# STM32F777 register map
File version: 1.6
CPU: CM7 r0p1, little endian, MPU, FPU, 4 interrupt priority bits
Registers are 32-bit, read-write, reset 0x0 unless marked. A register's access mark holds for its fields unless they carry their own. Offsets are from the block's base; [hi:lo] are bit positions; {n}, {i} and the like mark numbered series.

## TIM6 — Basic timers
Base 0x40001000
Same registers: TIM7 0x40001400
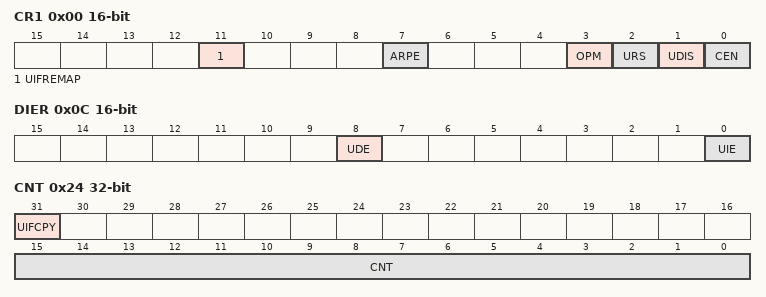
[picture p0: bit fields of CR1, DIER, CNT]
0x00 CR1 16-bit — control register 1
  [11] UIFREMAP — UIF status bit remapping
  [7] ARPE — Auto-reload preload enable
    0=Disabled (TIMx_APRR register is not buffered); 1=Enabled (TIMx_APRR register is buffered)
  [3] OPM — One-pulse mode
    0=Disabled (Counter is not stopped at update event); 1=Enabled (Counter stops counting at the next update event (clearing the CEN bit))
  [2] URS — Update request source
    0=AnyEvent (Any of counter overflow/underflow, setting UG, or update through slave mode, generates an update interrupt or DMA request); 1=CounterOnly (Only counter overflow/underflow generates an update interrupt or DMA request)
  [1] UDIS — Update disable
    0=Enabled (Update event enabled); 1=Disabled (Update event disabled)
  [0] CEN — Counter enable
    0=Disabled (Counter disabled); 1=Enabled (Counter enabled)
0x04 CR2 16-bit — control register 2
  [6:4] MMS — Master mode selection
    0=Reset (Use UG bit from TIMx_EGR register); 1=Enable (Use CNT bit from TIMx_CEN register); 2=Update (Use the update event)
0x0C DIER 16-bit — DMA/Interrupt enable register
  [8] UDE — Update DMA request enable
    0=Disabled (Update DMA request disabled); 1=Enabled (Update DMA request enabled)
  [0] UIE — Update interrupt enable
    0=Disabled (Update interrupt disabled); 1=Enabled (Update interrupt enabled)
0x10 SR 16-bit — status register
  [0] UIF write-0-clears — Update interrupt flag
    on read: 0=NoUpdateOccurred; 1=UpdatePending (Update interrupt pending) | on write: 0=Clear flag
0x14 EGR wo — event generation register
  [0] UG — Update generation
    1=Update (Re-initializes the timer counter and generates an update of the registers.)
0x24 CNT — counter
  [31] UIFCPY ro — UIF copy This bit is a read-only copy of the UIF bit of the TIMx_ISR register. If the UIFREMAP bit in the TIMxCR1 is reset, bit 31 is reserved and read at 0
  [15:0] CNT — Low counter value
0x24 CNT16 16-bit (alternate view of CNT) — 16-bit counter register
  [15:0] CNT — counter value
0x28 PSC 16-bit — prescaler
  [15:0] PSC — Prescaler value
0x2C ARR 16-bit reset 0xFFFF — auto-reload register
  [15:0] ARR — Low Auto-reload value

## CRC — Cryptographic processor
Base 0x40023000
0x00 DR reset 0xFFFFFFFF — Data register
  [31:0] DR — Data Register
0x00 DR8 8-bit reset 0xFF (alternate view of DR) — Data register - byte sized
  [7:0] DR8 — Data register bits
0x00 DR16 16-bit reset 0xFFFF (alternate view of DR) — Data register - half-word sized
  [15:0] DR16 — Data register bits
0x04 IDR — Independent Data register
  [7:0] IDR
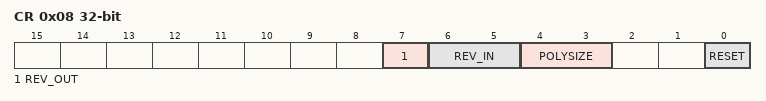
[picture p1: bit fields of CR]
0x08 CR wo — Control register
  [7] REV_OUT rw — Reverse output data
    0=Normal (Bit order not affected); 1=Reversed (Bit reversed output)
  [6:5] REV_IN rw — Reverse input data
    0=Normal (Bit order not affected); 1=Byte (Bit reversal done by byte); 2=HalfWord (Bit reversal done by half-word); 3=Word (Bit reversal done by word)
  [4:3] POLYSIZE rw — Polynomial size
    0=32-bit polynomial; 1=16-bit polynomial; 2=8-bit polynomial; 3=7-bit polynomial
  [0] RESET — RESET bit
    1=Resets the CRC calculation unit and sets the data register to 0xFFFF FFFF
0x10 INIT — Initial CRC value
  [31:0] INIT — Programmable initial CRC value
0x14 POL — CRC polynomial
  [31:0] POL — Programmable polynomial

## EXTI — External interrupt/event controller
Base 0x40013C00
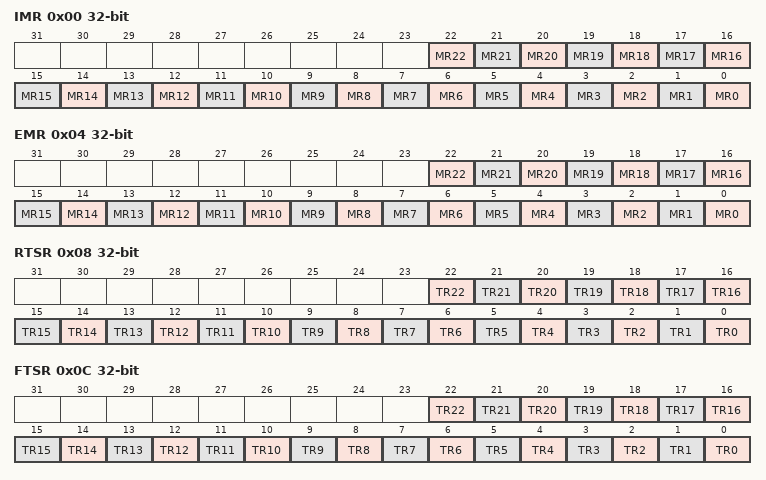
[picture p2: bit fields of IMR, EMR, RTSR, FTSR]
0x00 IMR — Interrupt mask register (EXTI_IMR)
  [n] MR{n} (n=0..22) — Interrupt Mask on line {n}
    0=Masked (Interrupt request line is masked); 1=Unmasked (Interrupt request line is unmasked)
0x04 EMR — Event mask register (EXTI_EMR)
  [n] MR{n} (n=0..22) — Event Mask on line {n}
    0=Masked (Event request line is masked); 1=Unmasked (Event request line is unmasked)
0x08 RTSR — Rising Trigger selection register (EXTI_RTSR)
  [n] TR{n} (n=0..22) — Rising trigger event configuration of line {n}
    0=Disabled (Rising edge trigger is disabled); 1=Enabled (Rising edge trigger is enabled)
0x0C FTSR — Falling Trigger selection register (EXTI_FTSR)
  [n] TR{n} (n=0..22) — Falling trigger event configuration of line {n}
    0=Disabled (Falling edge trigger is disabled); 1=Enabled (Falling edge trigger is enabled)
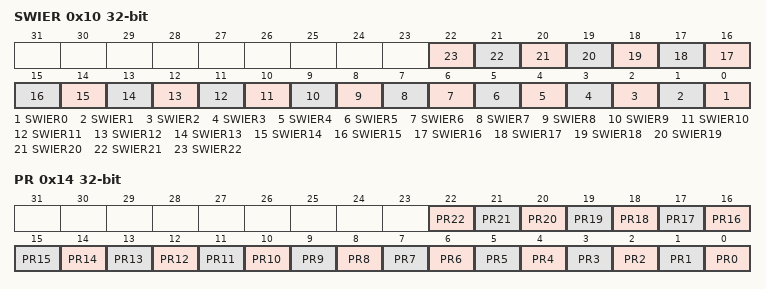
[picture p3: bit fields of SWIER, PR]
0x10 SWIER — Software interrupt event register (EXTI_SWIER)
  [n] SWIER{n} (n=0..22) — Software Interrupt on line {n}
    on write: 1=Pend (Generates an interrupt request)
0x14 PR — Pending register (EXTI_PR)
  [n] PR{n} (n=0..22) write-1-clears — Pending bit {n}
    on read: 0=NotPending (No trigger request occurred); 1=Pending (Selected trigger request occurred) | on write: 1=Clears pending bit
